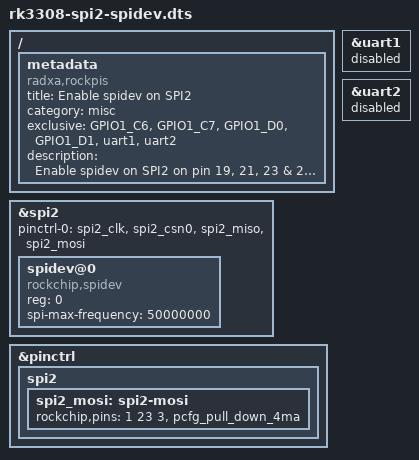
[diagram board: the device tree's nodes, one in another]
/* curl -OL https://github.com/radxa/overlays/raw/refs/heads/main/arch/arm64/boot/dts/rockchip/overlays/rk3308-spi2-spidev.dts */
/dts-v1/;
/plugin/;

/{
	metadata {
		title = "Enable spidev on SPI2";
		compatible = "radxa,rockpis", "radxa,rock-s0";
		category = "misc";
		exclusive = "GPIO1_C6", "GPIO1_C7", "GPIO1_D0", "GPIO1_D1", "uart1", "uart2";
		description = "Enable spidev on SPI2 on pin 19, 21, 23 & 24.";
	};

	fragment@0 {
		target = <&spi2>;

		__overlay__ {
			status = "okay";
			pinctrl-names = "default";
			pinctrl-0 = <&spi2_clk &spi2_csn0 &spi2_miso &spi2_mosi>;
			#address-cells = <1>;
			#size-cells = <0>;

			spidev@0 {
				compatible = "rockchip,spidev", "armbian,spi-dev";
				reg = <0>;
				spi-max-frequency = <50000000>;
			};
		};
	};

	fragment@1 {
		target = <&uart1>;

		__overlay__ {
			status = "disabled";
		};
	};

	fragment@2 {
		target = <&uart2>;

		__overlay__ {
			status = "disabled";
		};
	};

/* mosi idle low */
/* https://github.com/radxa/kernel/blob/fdd28476ab8bb898fb8030e0dabf4bbe67ddaf86/arch/arm64/boot/dts/rockchip/rk3308.dtsi#L1861 */
/* https://github.com/radxa/kernel/blob/fdd28476ab8bb898fb8030e0dabf4bbe67ddaf86/include/dt-bindings/pinctrl/rockchip.h#L35 */
/* #define RK_PC7 23 */
    fragment@3 {
        target = <&pinctrl>;

        __overlay__ {
            spi2 {
                spi2_mosi: spi2-mosi {
                    rockchip,pins = <1 23 3 &pcfg_pull_down_4ma>;
                };
            };
        };
    };
};
